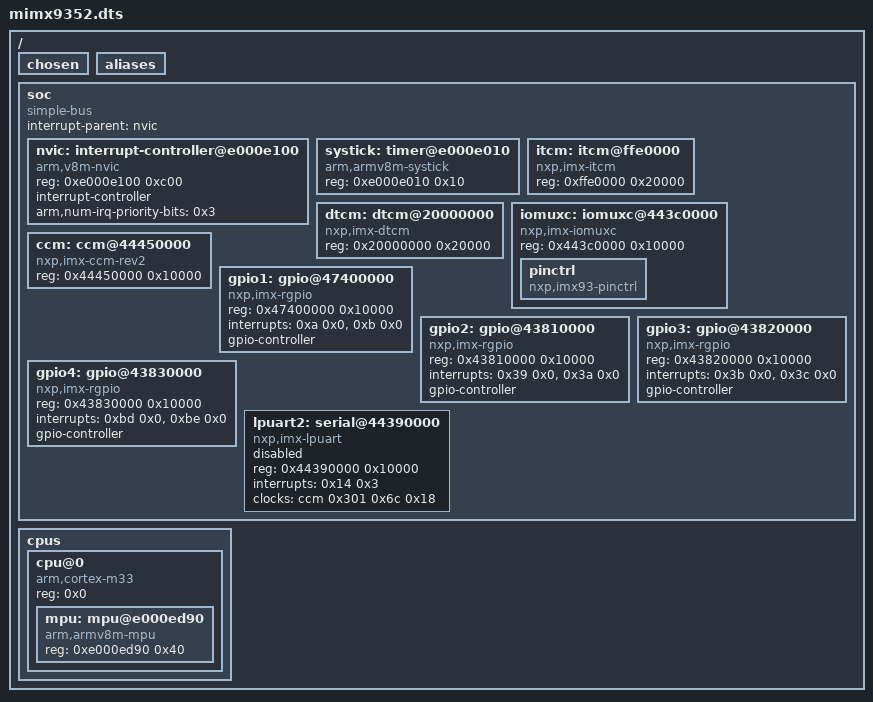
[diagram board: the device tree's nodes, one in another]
/dts-v1/;

/ {
	#address-cells = < 0x1 >;
	#size-cells = < 0x1 >;
	chosen {
	};
	aliases {
	};
	soc {
		#address-cells = < 0x1 >;
		#size-cells = < 0x1 >;
		compatible = "simple-bus";
		interrupt-parent = < &nvic >;
		ranges;
		nvic: interrupt-controller@e000e100 {
			#address-cells = < 0x1 >;
			compatible = "arm,v8m-nvic";
			reg = < 0xe000e100 0xc00 >;
			interrupt-controller;
			#interrupt-cells = < 0x2 >;
			arm,num-irq-priority-bits = < 0x3 >;
			phandle = < 0x1 >;
		};
		systick: timer@e000e010 {
			compatible = "arm,armv8m-systick";
			reg = < 0xe000e010 0x10 >;
		};
		itcm: itcm@ffe0000 {
			compatible = "nxp,imx-itcm";
			reg = < 0xffe0000 0x20000 >;
		};
		dtcm: dtcm@20000000 {
			compatible = "nxp,imx-dtcm";
			reg = < 0x20000000 0x20000 >;
		};
		iomuxc: iomuxc@443c0000 {
			compatible = "nxp,imx-iomuxc";
			reg = < 0x443c0000 0x10000 >;
			status = "okay";
			pinctrl: pinctrl {
				status = "okay";
				compatible = "nxp,imx93-pinctrl";
			};
		};
		ccm: ccm@44450000 {
			compatible = "nxp,imx-ccm-rev2";
			reg = < 0x44450000 0x10000 >;
			#clock-cells = < 0x3 >;
			phandle = < 0x2 >;
		};
		gpio1: gpio@47400000 {
			compatible = "nxp,imx-rgpio";
			reg = < 0x47400000 0x10000 >;
			interrupts = < 0xa 0x0 >, < 0xb 0x0 >;
			gpio-controller;
			#gpio-cells = < 0x2 >;
		};
		gpio2: gpio@43810000 {
			compatible = "nxp,imx-rgpio";
			reg = < 0x43810000 0x10000 >;
			interrupts = < 0x39 0x0 >, < 0x3a 0x0 >;
			gpio-controller;
			#gpio-cells = < 0x2 >;
		};
		gpio3: gpio@43820000 {
			compatible = "nxp,imx-rgpio";
			reg = < 0x43820000 0x10000 >;
			interrupts = < 0x3b 0x0 >, < 0x3c 0x0 >;
			gpio-controller;
			#gpio-cells = < 0x2 >;
		};
		gpio4: gpio@43830000 {
			compatible = "nxp,imx-rgpio";
			reg = < 0x43830000 0x10000 >;
			interrupts = < 0xbd 0x0 >, < 0xbe 0x0 >;
			gpio-controller;
			#gpio-cells = < 0x2 >;
		};
		lpuart2: serial@44390000 {
			compatible = "nxp,imx-lpuart", "nxp,kinetis-lpuart";
			reg = < 0x44390000 0x10000 >;
			interrupts = < 0x14 0x3 >;
			clocks = < &ccm 0x301 0x6c 0x18 >;
			status = "disabled";
		};
	};
	cpus {
		#address-cells = < 0x1 >;
		#size-cells = < 0x0 >;
		cpu@0 {
			device_type = "cpu";
			compatible = "arm,cortex-m33";
			reg = < 0x0 >;
			#address-cells = < 0x1 >;
			#size-cells = < 0x1 >;
			mpu: mpu@e000ed90 {
				compatible = "arm,armv8m-mpu";
				reg = < 0xe000ed90 0x40 >;
			};
		};
	};
};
